# ATA6613C device description
Architecture: AVR8; Family: megaAVR
Registers are 8-bit, access not given, no defined reset value unless marked. A register's access mark holds for its fields unless they carry their own. Offsets are from the block's base; [hi:lo] are bit positions; {n}, {i} and the like mark numbered series.

## AD_CONVERTER
Instances: AD_CONVERTER 0x00
0x78 ADC 16-bit — ADC Data Register Bytes
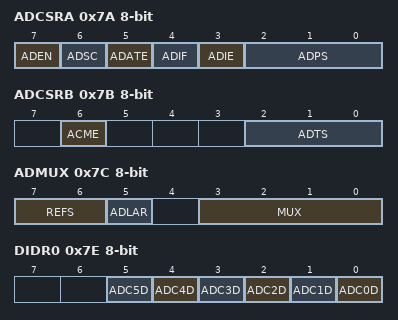
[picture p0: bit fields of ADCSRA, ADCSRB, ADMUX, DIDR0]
0x7A ADCSRA — The ADC Control and Status register A
  [7] ADEN — ADC Enable
  [6] ADSC — ADC Start Conversion
  [5] ADATE — ADC Auto Trigger Enable
  [4] ADIF — ADC Interrupt Flag
  [3] ADIE — ADC Interrupt Enable
  [2:0] ADPS — ADC Prescaler Select Bits
    0=2; 1=2; 2=4; 3=8; 4=16; 5=32; 6=64; 7=128
0x7B ADCSRB — The ADC Control and Status register B
  [6] ACME
  [2:0] ADTS — ADC Auto Trigger Source bits
    0=Free Running mode; 1=Analog Comparator; 2=External Interrupt Request 0; 3=Timer/Counter0 Compare Match A; 4=Timer/Counter0 Overflow; 5=Timer/Counter1 Compare Match B; 6=Timer/Counter1 Overflow; 7=Timer/Counter1 Capture Event
0x7C ADMUX — The ADC multiplexer Selection Register
  [7:6] REFS — Reference Selection Bits
    0=AREF, Internal Vref turned off; 1=AVCC with external capacitor at AREF pin; 3=Internal 1.1V Voltage Reference with external capacitor at AREF pin
  [5] ADLAR — Left Adjust Result
  [3:0] MUX — Analog Channel and Gain Selection Bits
0x7E DIDR0 — Digital Input Disable Register
  [n] ADC{n}D (n=0..5)

## ANALOG_COMPARATOR
Instances: ANALOG_COMPARATOR 0x00
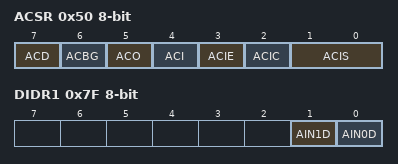
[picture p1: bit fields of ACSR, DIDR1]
0x50 ACSR — Analog Comparator Control And Status Register
  [7] ACD — Analog Comparator Disable
  [6] ACBG — Analog Comparator Bandgap Select
  [5] ACO — Analog Compare Output
  [4] ACI — Analog Comparator Interrupt Flag
  [3] ACIE — Analog Comparator Interrupt Enable
  [2] ACIC — Analog Comparator Input Capture Enable
  [1:0] ACIS — Analog Comparator Interrupt Mode Select bits
    0=Interrupt on Toggle; 2=Interrupt on Falling Edge; 3=Interrupt on Rising Edge
0x7F DIDR1 — Digital Input Disable Register 1
  [1] AIN1D — AIN1 Digital Input Disable
  [0] AIN0D — AIN0 Digital Input Disable

## PORTB
Instances: PORTB 0x00
0x23 PINB — Port B Input Pins
0x24 DDRB — Port B Data Direction Register
  [7:0] DDB — Port B Data Direction Register bits
0x25 PORTB — Port B Data Register

## PORTC
Instances: PORTC 0x00
0x26 PINC bits used 6:0 — Port C Input Pins
0x27 DDRC — Port C Data Direction Register
  [6:0] DDC — Port C Data Direction Register bits
0x28 PORTC bits used 6:0 — Port C Data Register

## PORTD
Instances: PORTD 0x00
0x29 PIND — Port D Input Pins
0x2A DDRD — Port D Data Direction Register
  [7:0] DDD — Port D Data Direction Register bits
0x2B PORTD — Port D Data Register

## TIMER_COUNTER_0
Instances: TIMER_COUNTER_0 0x00
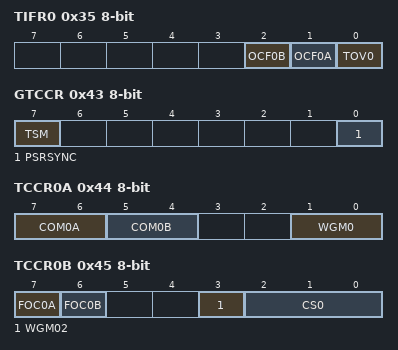
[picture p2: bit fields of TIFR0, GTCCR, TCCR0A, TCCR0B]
0x35 TIFR0 — Timer/Counter0 Interrupt Flag register
  [2] OCF0B — Timer/Counter0 Output Compare Flag 0B
  [1] OCF0A — Timer/Counter0 Output Compare Flag 0A
  [0] TOV0 — Timer/Counter0 Overflow Flag
0x43 GTCCR — General Timer/Counter Control Register
  [7] TSM — Timer/Counter Synchronization Mode
  [0] PSRSYNC — Prescaler Reset Timer/Counter1 and Timer/Counter0
0x44 TCCR0A — Timer/Counter Control Register A
  [7:6] COM0A — Compare Output Mode, Phase Correct PWM Mode
  [5:4] COM0B — Compare Output Mode, Fast PWm
  [1:0] WGM0 — Waveform Generation Mode
0x45 TCCR0B — Timer/Counter Control Register B
  [7] FOC0A — Force Output Compare A
  [6] FOC0B — Force Output Compare B
  [3] WGM02
  [2:0] CS0 — Clock Select
    0=No Clock Source (Stopped); 1=Running, No Prescaling; 2=Running, CLK/8; 3=Running, CLK/64; 4=Running, CLK/256; 5=Running, CLK/1024; 6=Running, ExtClk Tx Falling Edge; 7=Running, ExtClk Tx Rising Edge
0x46 TCNT0 — Timer/Counter0
0x47 OCR0A — Timer/Counter0 Output Compare Register
0x48 OCR0B — Timer/Counter0 Output Compare Register
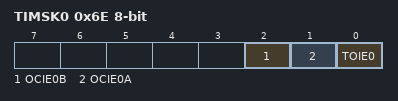
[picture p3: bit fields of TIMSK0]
0x6E TIMSK0 — Timer/Counter0 Interrupt Mask Register
  [2] OCIE0B — Timer/Counter0 Output Compare Match B Interrupt Enable
  [1] OCIE0A — Timer/Counter0 Output Compare Match A Interrupt Enable
  [0] TOIE0 — Timer/Counter0 Overflow Interrupt Enable
